# ATSAMA5D27 register map
Vendor: Microchip Technology Inc.; File version: 1.0
CPU: CA5 r0p1, little endian, no MPU, no FPU, 4 interrupt priority bits
Address unit: 32 bits
Registers are 32-bit, read-write, reset 0x0 unless marked. A register's access mark holds for its fields unless they carry their own. Offsets are from the block's base; [hi:lo] are bit positions; 'fields as' and 'values as' point back to an identical list.

## I2SC0 — Inter-IC Sound Controller
Base 0xF8050000
Same registers: I2SC1 0xFC04C000
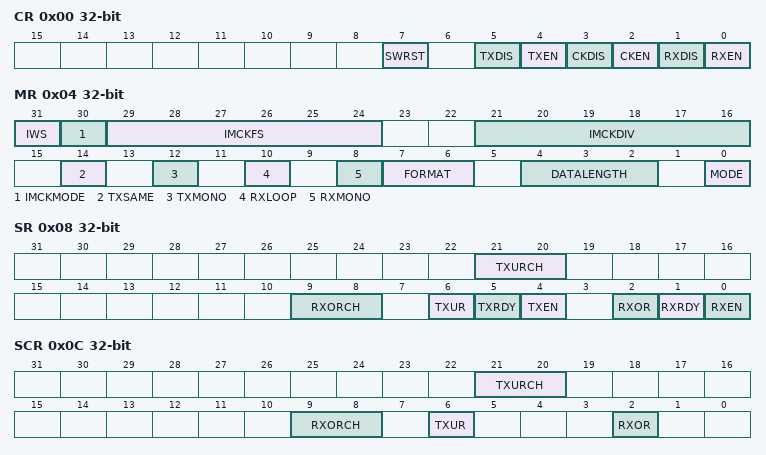
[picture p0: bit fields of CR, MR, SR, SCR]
0x00 CR wo — Control Register
  [7] SWRST rw — Software Reset
  [5] TXDIS rw — Transmitter Disable
  [4] TXEN rw — Transmitter Enable
  [3] CKDIS rw — Clocks Disable
  [2] CKEN rw — Clocks Enable
  [1] RXDIS rw — Receiver Disable
  [0] RXEN rw — Receiver Enable
0x04 MR — Mode Register
  [31] IWS — I2SC_WS Slot Width
  [30] IMCKMODE — Master Clock Mode
  [29:24] IMCKFS — Master Clock to fs Ratio
    0=M2SF32 (Sample frequency ratio set to 32); 1=M2SF64 (Sample frequency ratio set to 64); 2=M2SF96 (Sample frequency ratio set to 96); 3=M2SF128 (Sample frequency ratio set to 128); 5=M2SF192 (Sample frequency ratio set to 192); 7=M2SF256 (Sample frequency ratio set to 256); 11=M2SF384 (Sample frequency ratio set to 384); 15=M2SF512 (Sample frequency ratio set to 512); 23=M2SF768 (Sample frequency ratio set to 768); 31=M2SF1024 (Sample frequency ratio set to 1024); 47=M2SF1536 (Sample frequency ratio set to 1536); 63=M2SF2048 (Sample frequency ratio set to 2048)
  [21:16] IMCKDIV — Selected Clock to I2SC Master Clock Ratio
  [14] TXSAME — Transmit Data when Underrun
  [12] TXMONO — Transmit Mono
  [10] RXLOOP — Loopback Test Mode
  [8] RXMONO — Receive Mono
  [7:6] FORMAT — Data Format
    0=I2S (I2S format, stereo with I2SC_WS low for left channel, and MSB of sample starting one I2SC_CK period after I2SC_WS edge); 1=LJ (Left-justified format, stereo with I2SC_WS high for left channel, and MSB of sample starting on I2SC_WS edge)
  [4:2] DATALENGTH — Data Word Length
    0=_32_BITS (Data length is set to 32 bits); 1=_24_BITS (Data length is set to 24 bits); 2=_20_BITS (Data length is set to 20 bits); 3=_18_BITS (Data length is set to 18 bits); 4=_16_BITS (Data length is set to 16 bits); 5=_16_BITS_COMPACT (Data length is set to 16-bit compact stereo. Left sample in bits 15:0 and right sample in bits 31:16 of same word.); 6=_8_BITS (Data length is set to 8 bits); 7=_8_BITS_COMPACT (Data length is set to 8-bit compact stereo. Left sample in bits 7:0 and right sample in bits 15:8 of the same word.)
  [0] MODE — Inter-IC Sound Controller Mode
    0=SLAVE (I2SC_CK and I2SC_WS pin inputs used as bit clock and word select/frame synchronization.); 1=MASTER (Bit clock and word select/frame synchronization generated by I2SC from MCK and output to I2SC_CK and I2SC_WS pins. Peripheral clock or GCLK is output as master clock on I2SC_MCK if I2SC_MR.IMCKMODE is set.)
0x08 SR ro — Status Register
  [21:20] TXURCH rw — Transmit Underrun Channel
  [9:8] RXORCH rw — Receive Overrun Channel
  [6] TXUR rw — Transmit Underrun
  [5] TXRDY rw — Transmit Ready
  [4] TXEN rw — Transmitter Enabled
  [2] RXOR rw — Receive Overrun
  [1] RXRDY rw — Receive Ready
  [0] RXEN rw — Receiver Enabled
0x0C SCR wo — Status Clear Register
  [21:20] TXURCH rw — Transmit Underrun Per Channel Status Clear
  [9:8] RXORCH rw — Receive Overrun Per Channel Status Clear
  [6] TXUR rw — Transmit Underrun Status Clear
  [2] RXOR rw — Receive Overrun Status Clear
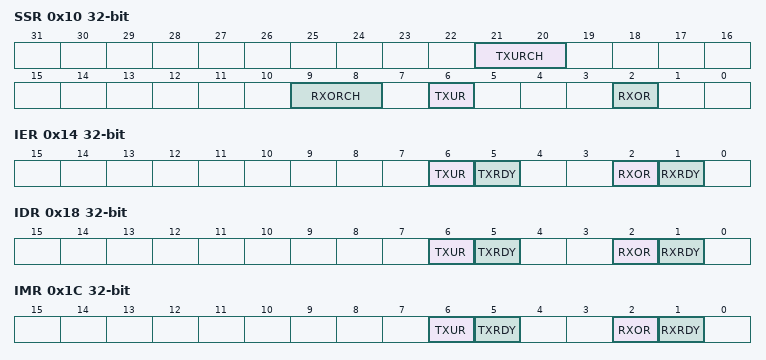
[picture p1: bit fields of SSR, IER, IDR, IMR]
0x10 SSR wo — Status Set Register
  [21:20] TXURCH rw — Transmit Underrun Per Channel Status Set
  [9:8] RXORCH rw — Receive Overrun Per Channel Status Set
  [6] TXUR rw — Transmit Underrun Status Set
  [2] RXOR rw — Receive Overrun Status Set
0x14 IER wo — Interrupt Enable Register
  [6] TXUR rw — Transmit Underflow Interrupt Enable
  [5] TXRDY rw — Transmit Ready Interrupt Enable
  [2] RXOR rw — Receiver Overrun Interrupt Enable
  [1] RXRDY rw — Receiver Ready Interrupt Enable
0x18 IDR wo — Interrupt Disable Register
  [6] TXUR rw — Transmit Underflow Interrupt Disable
  [5] TXRDY rw — Transmit Ready Interrupt Disable
  [2] RXOR rw — Receiver Overrun Interrupt Disable
  [1] RXRDY rw — Receiver Ready Interrupt Disable
0x1C IMR ro — Interrupt Mask Register
  fields as IDR
0x20 RHR ro — Receiver Holding Register
  [31:0] RHR rw
0x24 THR wo — Transmitter Holding Register
  [31:0] THR rw
